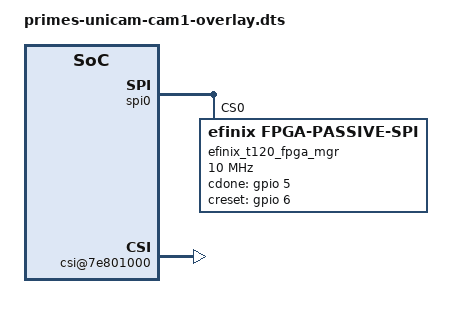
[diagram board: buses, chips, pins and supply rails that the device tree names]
/dts-v1/;
/plugin/;

#include <dt-bindings/gpio/gpio.h>

/ {
  fragment@0 {
    target = <&spi0>;
    __overlay__ {
      status = "okay";
      efinix_t120_fpga_mgr: fpga-mgr@0 {
        compatible = "efinix,fpga-passive-spi";
        reg = <0>;
        spi-max-frequency = <10000000>;
        spi-cpol;
        spi-cpha;
        cdone-gpios  = <&gpio 5 GPIO_ACTIVE_HIGH>;
        creset-gpios = <&gpio 6 GPIO_ACTIVE_HIGH>;
      };
    };
  };
  fragment@1 {
    target-path = "/soc";
    __overlay__ {
      csi@7e801000 {
        compatible = "primes,bcm2835-unicam-primes-generic-fpga";
        status = "okay";
        fpga-mgr = <&efinix_t120_fpga_mgr>;
        fpga-i2c-mipi-config {
          busnum = <10>;
          reg = <0x41>;
        };
        fpga-i2c-amplifier-config {
          busnum = <10>;
          reg = <0x73>;
        };
      };
    };
  };
};
